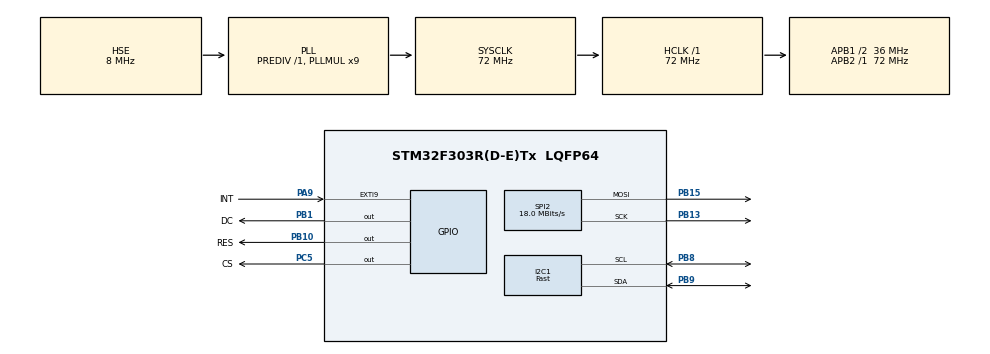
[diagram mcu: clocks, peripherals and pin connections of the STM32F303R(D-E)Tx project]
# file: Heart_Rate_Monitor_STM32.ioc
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Mcu.Family=STM32F3
RCC.PLLSourceVirtual=RCC_PLLSOURCE_HSE
RCC.CortexFreq_Value=72000000
I2C1.I2C_Speed_Mode=I2C_Fast
SPI2.VirtualType=VM_MASTER
PA9.GPIO_Label=INT
RCC.SYSCLKSourceVirtual=RCC_SYSCLKSOURCE_PLLCLK
RCC.APB1CLKDivider=RCC_HCLK_DIV2
PB13.Signal=SPI2_SCK
PB15.Signal=SPI2_MOSI
ProjectManager.StackSize=0x400
PA13.Signal=SYS_JTMS-SWDIO
SPI2.CLKPolarity=SPI_POLARITY_HIGH
ProjectManager.TargetToolchain=STM32CubeIDE
PB10.GPIO_Label=RES
RCC.HCLKFreq_Value=72000000
PB9.Mode=I2C
RCC.APB2TimFreq_Value=72000000
PA9.Signal=GPXTI9
I2C1.Timing=0x0000020B
RCC.USBFreq_Value=72000000
RCC.LSE_VALUE=32768
RCC.AHBFreq_Value=72000000
SPI2.BaudRatePrescaler=SPI_BAUDRATEPRESCALER_2
PF0-OSC_IN.Mode=HSE-External-Oscillator
PB10.Signal=GPIO_Output
RCC.HSE_VALUE=8000000
board=custom
RCC.PLLMUL=RCC_PLL_MUL9
PB15.Mode=TX_Only_Simplex_Unidirect_Master
RCC.APB2Freq_Value=72000000
PA14.Mode=Serial_Wire
PB1.GPIO_Label=DC
SPI2.CalculateBaudRate=18.0 MBits/s
PA13.Mode=Serial_Wire
Mcu.Name=STM32F303R(D-E)Tx
RCC.SYSCLKFreq_VALUE=72000000
Mcu.Package=LQFP64
PB9.Signal=I2C1_SDA
PB1.Signal=GPIO_Output
SPI2.Mode=SPI_MODE_MASTER
PC5.GPIO_Label=CS
NVIC.EXTI9_5_IRQn=true\:0\:0\:false\:false\:true\:true\:true
PA14.Signal=SYS_JTCK-SWCLK
ProjectManager.HeapSize=0x200
PB9.GPIO_PuPdOD=GPIO_NOPULL
SPI2.CLKPhase=SPI_PHASE_2EDGE
PB8.GPIO_PuPdOD=GPIO_NOPULL
RCC.HSI_VALUE=8000000
NVIC.PriorityGroup=NVIC_PRIORITYGROUP_4
PB8.Mode=I2C
PA9.GPIO_ModeDefaultEXTI=GPIO_MODE_IT_FALLING
RCC.APB1TimFreq_Value=72000000
PB8.Signal=I2C1_SCL
SPI2.DataSize=SPI_DATASIZE_8BIT
SPI2.Direction=SPI_DIRECTION_2LINES
PC5.Signal=GPIO_Output
PB13.Mode=TX_Only_Simplex_Unidirect_Master
PF0-OSC_IN.Signal=RCC_OSC_IN
PF1-OSC_OUT.Mode=HSE-External-Oscillator
RCC.APB1Freq_Value=36000000
PF1-OSC_OUT.Signal=RCC_OSC_OUT

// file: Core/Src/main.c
/* USER CODE BEGIN Header */
/**
  ******************************************************************************
  * @file           : main.c
  * @brief          : Main program body
  ******************************************************************************
  * @attention
  *
  * <h2><center>&copy; Copyright (c) 2021 STMicroelectronics.
  * All rights reserved.</center></h2>
  *
  * This software component is licensed by ST under BSD 3-Clause license,
  * the "License"; You may not use this file except in compliance with the
  * License. You may obtain a copy of the License at:
  *                        opensource.org/licenses/BSD-3-Clause
  *
  ******************************************************************************
  */
/* USER CODE END Header */
#include "main.h"
#include "i2c.h"
#include "spi.h"
#include "gpio.h"
#include "bitmaps.h"
/* USER CODE BEGIN Includes */
#include "MAX30102.h"
#include "SSD1331.h"
#include "screen.h"
/* USER CODE END Includes */

void SystemClock_Config(void);

int main(void)
{

  /* MCU Configuration--------------------------------------------------------*/

  /* Reset of all peripherals, Initializes the Flash interface and the Systick. */
  HAL_Init();

  /* Configure the system clock */
  SystemClock_Config();

  /* Initialize all configured peripherals */
  MX_GPIO_Init();
  MX_I2C1_Init();
  MX_SPI2_Init();
  /* USER CODE BEGIN 2 */
  ssd1331_init();
  Max30102_Init(&hi2c1);
  /* USER CODE END 2 */

  /* Infinite loop */
  /* USER CODE BEGIN WHILE */
  while (1)
  {
    Max30102_StateMachine();

    /* USER CODE END WHILE */

  }
}

void SystemClock_Config(void)
{
  RCC_OscInitTypeDef RCC_OscInitStruct = {0};
  RCC_ClkInitTypeDef RCC_ClkInitStruct = {0};
  RCC_PeriphCLKInitTypeDef PeriphClkInit = {0};

  /** Initializes the RCC Oscillators according to the specified parameters
  * in the RCC_OscInitTypeDef structure.
  */
  RCC_OscInitStruct.OscillatorType = RCC_OSCILLATORTYPE_HSI | RCC_OSCILLATORTYPE_HSE;
  RCC_OscInitStruct.HSEState = RCC_HSE_ON;
  RCC_OscInitStruct.HSIState = RCC_HSI_ON;
  RCC_OscInitStruct.HSICalibrationValue = RCC_HSICALIBRATION_DEFAULT;
  RCC_OscInitStruct.PLL.PLLState = RCC_PLL_ON;
  RCC_OscInitStruct.PLL.PLLSource = RCC_PLLSOURCE_HSE;
  RCC_OscInitStruct.PLL.PLLMUL = RCC_PLL_MUL9;
  RCC_OscInitStruct.PLL.PREDIV = RCC_PREDIV_DIV1;
  if (HAL_RCC_OscConfig(&RCC_OscInitStruct) != HAL_OK)
  {
    Error_Handler();
  }
  /** Initializes the CPU, AHB and APB buses clocks
  */
  RCC_ClkInitStruct.ClockType = RCC_CLOCKTYPE_HCLK | RCC_CLOCKTYPE_SYSCLK | RCC_CLOCKTYPE_PCLK1 | RCC_CLOCKTYPE_PCLK2;
  RCC_ClkInitStruct.SYSCLKSource = RCC_SYSCLKSOURCE_PLLCLK;
  RCC_ClkInitStruct.AHBCLKDivider = RCC_SYSCLK_DIV1;
  RCC_ClkInitStruct.APB1CLKDivider = RCC_HCLK_DIV2;
  RCC_ClkInitStruct.APB2CLKDivider = RCC_HCLK_DIV1;

  if (HAL_RCC_ClockConfig(&RCC_ClkInitStruct, FLASH_LATENCY_2) != HAL_OK)
  {
    Error_Handler();
  }
  PeriphClkInit.PeriphClockSelection = RCC_PERIPHCLK_I2C1;
  PeriphClkInit.I2c1ClockSelection = RCC_I2C1CLKSOURCE_HSI;
  if (HAL_RCCEx_PeriphCLKConfig(&PeriphClkInit) != HAL_OK)
  {
    Error_Handler();
  }
}

/* USER CODE BEGIN 4 */
void HAL_GPIO_EXTI_Callback(uint16_t GPIO_Pin)
{
  if (GPIO_Pin == INT_Pin)
  {
    Max30102_InterruptCallback();
  }
}
/* USER CODE END 4 */

void Error_Handler(void)
{
  __disable_irq();
  while (1)
  {
  }
}

/************************ (C) COPYRIGHT STMicroelectronics *****END OF FILE****/
